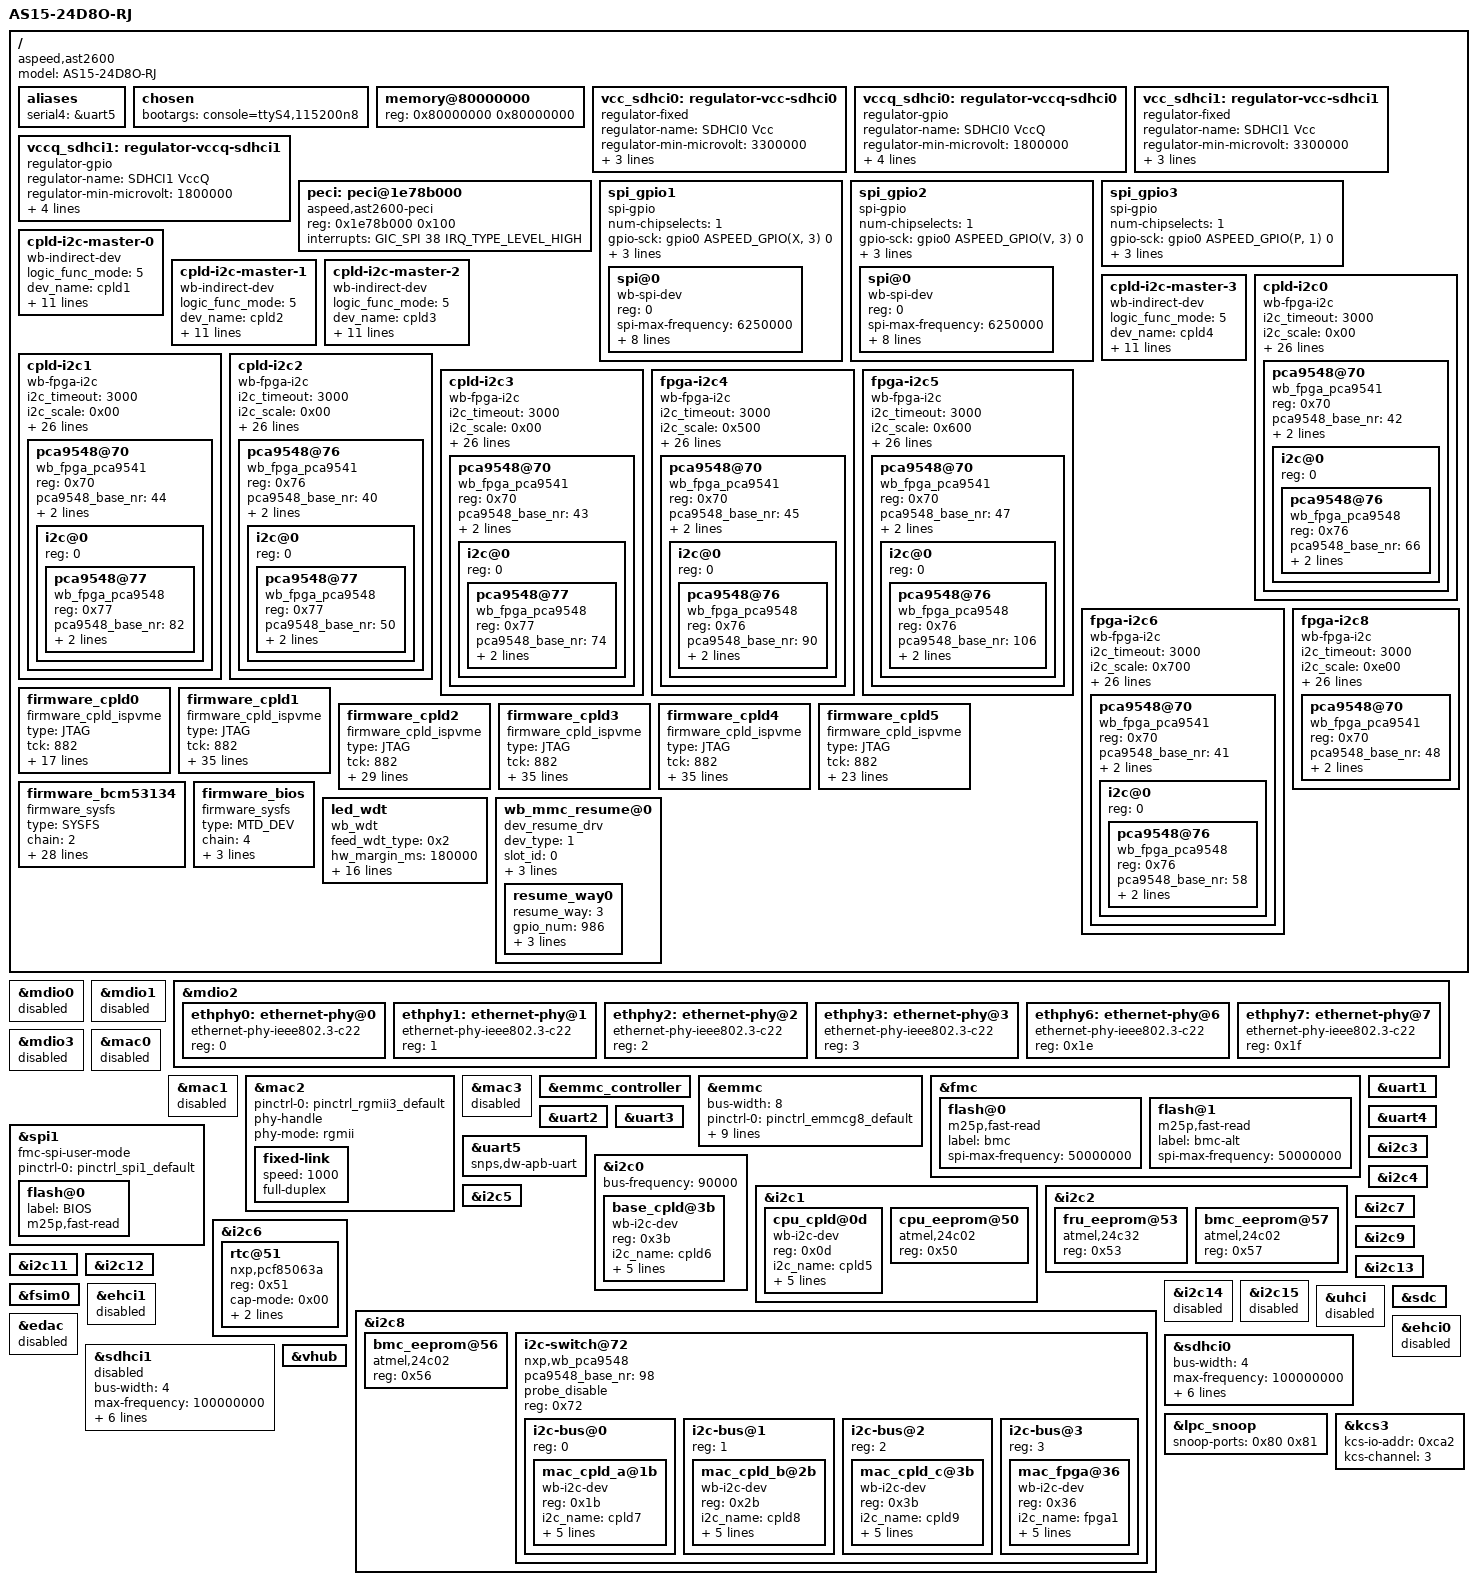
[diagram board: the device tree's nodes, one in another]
// SPDX-License-Identifier: GPL-2.0-or-later
// Copyright 2019 IBM Corp.

/dts-v1/;

#include "aspeed-g6.dtsi"
#include <dt-bindings/gpio/aspeed-gpio.h>

/ {
    model = "AS15-24D8O-RJ";
    compatible = "aspeed,ast2600";

    aliases {
        serial4 = &uart5;
    };

    chosen {
        bootargs = "console=ttyS4,115200n8";
    };

    memory@80000000 {
        device_type = "memory";
        reg = <0x80000000 0x80000000>;
    };

    vcc_sdhci0: regulator-vcc-sdhci0 {
        compatible = "regulator-fixed";
        regulator-name = "SDHCI0 Vcc";
        regulator-min-microvolt = <3300000>;
        regulator-max-microvolt = <3300000>;
        gpios = <&gpio0 ASPEED_GPIO(V, 0) GPIO_ACTIVE_HIGH>;
        enable-active-high;
    };

    vccq_sdhci0: regulator-vccq-sdhci0 {
        compatible = "regulator-gpio";
        regulator-name = "SDHCI0 VccQ";
        regulator-min-microvolt = <1800000>;
        regulator-max-microvolt = <3300000>;
        gpios = <&gpio0 ASPEED_GPIO(V, 1) GPIO_ACTIVE_HIGH>;
        gpios-states = <1>;
        states = <3300000 1>,<1800000 0>;
    };

    vcc_sdhci1: regulator-vcc-sdhci1 {
        compatible = "regulator-fixed";
        regulator-name = "SDHCI1 Vcc";
        regulator-min-microvolt = <3300000>;
        regulator-max-microvolt = <3300000>;
        gpios = <&gpio0 ASPEED_GPIO(V, 2) GPIO_ACTIVE_HIGH>;
        enable-active-high;
    };

    vccq_sdhci1: regulator-vccq-sdhci1 {
        compatible = "regulator-gpio";
        regulator-name = "SDHCI1 VccQ";
        regulator-min-microvolt = <1800000>;
        regulator-max-microvolt = <3300000>;
        gpios = <&gpio0 ASPEED_GPIO(V, 3) GPIO_ACTIVE_HIGH>;
        gpios-states = <1>;
        states = <3300000 1>,<1800000 0>;
    };

    peci: peci@1e78b000 {
        compatible = "aspeed,ast2600-peci";
        reg = <0x1e78b000 0x100>;
        interrupts = <GIC_SPI 38 IRQ_TYPE_LEVEL_HIGH>;
    };

    spi_gpio1 {
        compatible = "spi-gpio";
        status = "okay";
        #address-cells = <1>;
        #size-cells = <0>;
        num-chipselects = <1>;

        gpio-sck = <&gpio0 ASPEED_GPIO(X, 3) 0>;
        gpio-mosi = <&gpio0 ASPEED_GPIO(X, 4) 0>;
        gpio-miso = <&gpio0 ASPEED_GPIO(X, 5) 0>;
        cs-gpios = <&gpio0 ASPEED_GPIO(X, 0) 0>;
        spi@0 {
            compatible = "wb-spi-dev";
            reg = <0>;
            spi-max-frequency = <6250000>;
            spi-cpha;
            spi-cpol;
            spi_dev_name = "fpga0";
            data_bus_width    = <4>;
            addr_bus_width    = <4>;
            per_rd_len        = <4>;
            per_wr_len        = <4>;
            spi_len        = <0x2000>;
        };
    };

    spi_gpio2 {
        compatible = "spi-gpio";
        status = "okay";
        #address-cells = <1>;
        #size-cells = <0>;
        num-chipselects = <1>;

        gpio-sck = <&gpio0 ASPEED_GPIO(V, 3) 0>;
        gpio-mosi = <&gpio0 ASPEED_GPIO(Y, 2) 0>;
        gpio-miso = <&gpio0 ASPEED_GPIO(Y, 1) 0>;
        cs-gpios = <&gpio0 ASPEED_GPIO(Y, 3) 0>;

        spi@0 {
            compatible = "wb-spi-dev";
            reg = <0>;
            spi-max-frequency = <6250000>;
            spi-cpha;
            spi-cpol;
            spi_dev_name = "cpld0";
            data_bus_width    = <1>;
            addr_bus_width    = <2>;
            per_rd_len        = <1>;
            per_wr_len        = <1>;
            spi_len        = <0x140>;
        };
    };

    spi_gpio3 {
        compatible = "spi-gpio";
        status = "okay";
        #address-cells = <1>;
        #size-cells = <0>;
        num-chipselects = <1>;

        gpio-sck = <&gpio0 ASPEED_GPIO(P, 1) 0>;
        gpio-mosi = <&gpio0 ASPEED_GPIO(P, 3) 0>;
        gpio-miso = <&gpio0 ASPEED_GPIO(P, 2) 0>;
        cs-gpios = <&gpio0 ASPEED_GPIO(P, 4) 0>;
    };

    cpld-i2c-master-0 {
        compatible = "wb-indirect-dev";
        logic_func_mode = <5>;
        dev_name = "cpld1";
        logic_dev_name = "/dev/cpld0";
        data_bus_width    = <4>;
        addr_bus_width    = <1>;
        wr_data        = <0x100>;
        wr_data_width     = <4>;
        addr_low       = <0x104>;
        addr_high      = <0x105>;
        rd_data        = <0x106>;
        rd_data_width     = <4>;
        opt_ctl        = <0x10a>;
        indirect_len   = <0x200>;
    };

    cpld-i2c-master-1 {
        compatible = "wb-indirect-dev";
        logic_func_mode = <5>;
        dev_name = "cpld2";
        logic_dev_name = "/dev/cpld0";
        data_bus_width    = <4>;
        addr_bus_width    = <1>;
        wr_data        = <0x110>;
        wr_data_width     = <4>;
        addr_low       = <0x114>;
        addr_high      = <0x115>;
        rd_data        = <0x116>;
        rd_data_width     = <4>;
        opt_ctl        = <0x11a>;
        indirect_len   = <0x200>;
    };

    cpld-i2c-master-2 {
        compatible = "wb-indirect-dev";
        logic_func_mode = <5>;
        dev_name = "cpld3";
        logic_dev_name = "/dev/cpld0";
        data_bus_width    = <4>;
        addr_bus_width    = <1>;
        wr_data        = <0x120>;
        wr_data_width     = <4>;
        addr_low       = <0x124>;
        addr_high      = <0x125>;
        rd_data        = <0x126>;
        rd_data_width     = <4>;
        opt_ctl        = <0x12a>;
        indirect_len   = <0x200>;
    };

    cpld-i2c-master-3 {
        compatible = "wb-indirect-dev";
        logic_func_mode = <5>;
        dev_name = "cpld4";
        logic_dev_name = "/dev/cpld0";
        data_bus_width    = <4>;
        addr_bus_width    = <1>;
        wr_data        = <0x130>;
        wr_data_width     = <4>;
        addr_low       = <0x134>;
        addr_high      = <0x135>;
        rd_data        = <0x136>;
        rd_data_width     = <4>;
        opt_ctl        = <0x13a>;
        indirect_len   = <0x230>;
    };

   cpld-i2c0 {
       compatible = "wb-fpga-i2c";
       i2c_timeout             = <3000>;
       i2c_scale               = <0x00>;
       i2c_filter              = <0x04>;
       i2c_stretch             = <0x08>;
       i2c_ext_9548_exits_flag = <0x0c>;
       i2c_ext_9548_addr       = <0x10>;
       i2c_ext_9548_chan       = <0x14>;
       i2c_in_9548_chan        = <0x18>;
       i2c_slave               = <0x1c>;
       i2c_reg                 = <0x20>;
       i2c_reg_len             = <0x30>;
       i2c_data_len            = <0x34>;
       i2c_ctrl                = <0x38>;
       i2c_status              = <0x3c>;
       i2c_err_vec             = <0x48>;
       i2c_data_buf            = <0x100>;
       dev_name                = "/dev/cpld1";
       i2c_scale_value         = <0x4e>;
       i2c_filter_value        = <0x7c>;
       i2c_stretch_value       = <0x7c>;
       i2c_func_mode           = <6>;
       i2c_adap_reset_flag     = <0>;
       i2c_reset_addr          = <0x7c>;
       i2c_reset_on            = <0x00000001>;
       i2c_reset_off           = <0x00000000>;
       i2c_rst_delay_b         = <0>; /* delay time before reset(us) */
       i2c_rst_delay           = <1>; /* reset time(us) */
       i2c_rst_delay_a         = <1>; /* delay time after reset(us) */
       pca9548@70 {
           compatible = "wb_fpga_pca9541";
           reg = <0x70>;  
           #address-cells = <1>;
           #size-cells = <0>;
           pca9548_base_nr = <42>;
           fpga_9548_flag = <1>;        /* 1: internal 9548 2: external 9548 */
           fpga_9548_reset_flag = <0>;  /* 1: reset, 0: no bit */
           i2c@0 {
               reg = <0>;
               pca9548@76 {
                   compatible = "wb_fpga_pca9548";
                   reg = <0x76>;  
                   #address-cells = <1>;
                   #size-cells = <0>;
                   pca9548_base_nr = <66>;
                   fpga_9548_flag = <2>;
                   fpga_9548_reset_flag = <1>;
               };
           };
       };
   };

    cpld-i2c1 {
        compatible = "wb-fpga-i2c";
        i2c_timeout             = <3000>;
        i2c_scale               = <0x00>;
        i2c_filter              = <0x04>;
        i2c_stretch             = <0x08>;
        i2c_ext_9548_exits_flag = <0x0c>;
        i2c_ext_9548_addr       = <0x10>;
        i2c_ext_9548_chan       = <0x14>;
        i2c_in_9548_chan        = <0x18>;
        i2c_slave               = <0x1c>;
        i2c_reg                 = <0x20>;
        i2c_reg_len             = <0x30>;
        i2c_data_len            = <0x34>;
        i2c_ctrl                = <0x38>;
        i2c_status              = <0x3c>;
        i2c_err_vec             = <0x48>;
        i2c_data_buf            = <0x100>;
        dev_name                = "/dev/cpld2";
        i2c_scale_value         = <0x4e>;
        i2c_filter_value        = <0x7c>;
        i2c_stretch_value       = <0x7c>;
        i2c_func_mode           = <6>;
        i2c_adap_reset_flag     = <0>;
        i2c_reset_addr          = <0x7c>;
        i2c_reset_on            = <0x00000001>;
        i2c_reset_off           = <0x00000000>;
        i2c_rst_delay_b         = <0>; /* delay time before reset(us) */
        i2c_rst_delay           = <1>; /* reset time(us) */
        i2c_rst_delay_a         = <1>; /* delay time after reset(us) */
        pca9548@70 {
            compatible = "wb_fpga_pca9541";
            reg = <0x70>;  
            #address-cells = <1>;
            #size-cells = <0>;
            pca9548_base_nr = <44>;
            fpga_9548_flag = <1>;        /* 1: internal 9548 2: external 9548 */
            fpga_9548_reset_flag = <0>;  /* 1: reset, 0: no bit */
            i2c@0 {
                reg = <0>;
                pca9548@77 {
                    compatible = "wb_fpga_pca9548";
                    reg = <0x77>;  
                    #address-cells = <1>;
                    #size-cells = <0>;
                    pca9548_base_nr = <82>;
                    fpga_9548_flag = <2>;
                    fpga_9548_reset_flag = <1>;
                };
            };
        };
    };

    cpld-i2c2 {
        compatible = "wb-fpga-i2c";
        i2c_timeout             = <3000>;
        i2c_scale               = <0x00>;
        i2c_filter              = <0x04>;
        i2c_stretch             = <0x08>;
        i2c_ext_9548_exits_flag = <0x0c>;
        i2c_ext_9548_addr       = <0x10>;
        i2c_ext_9548_chan       = <0x14>;
        i2c_in_9548_chan        = <0x18>;
        i2c_slave               = <0x1c>;
        i2c_reg                 = <0x20>;
        i2c_reg_len             = <0x30>;
        i2c_data_len            = <0x34>;
        i2c_ctrl                = <0x38>;
        i2c_status              = <0x3c>;
        i2c_err_vec             = <0x48>;
        i2c_data_buf            = <0x100>;
        dev_name                = "/dev/cpld3";
        i2c_scale_value         = <0x4e>;
        i2c_filter_value        = <0x7c>;
        i2c_stretch_value       = <0x7c>;
        i2c_func_mode           = <6>;
        i2c_adap_reset_flag     = <0>;
        i2c_reset_addr          = <0x7c>;
        i2c_reset_on            = <0x00000001>;
        i2c_reset_off           = <0x00000000>;
        i2c_rst_delay_b         = <0>; /* delay time before reset(us) */
        i2c_rst_delay           = <1>; /* reset time(us) */
        i2c_rst_delay_a         = <1>; /* delay time after reset(us) */

        pca9548@76 {
            compatible = "wb_fpga_pca9541";
            reg = <0x76>;  
            #address-cells = <1>;
            #size-cells = <0>;
            pca9548_base_nr = <40>;
            fpga_9548_flag = <1>;        /* 1: internal 9548 2: external 9548 */
            fpga_9548_reset_flag = <0>;  /* 1: reset, 0: no bit */
            i2c@0 {
                reg = <0>;
                pca9548@77 {
                    compatible = "wb_fpga_pca9548";
                    reg = <0x77>;  
                    #address-cells = <1>;
                    #size-cells = <0>;
                    pca9548_base_nr = <50>;
                    fpga_9548_flag = <2>;
                    fpga_9548_reset_flag = <1>;
                };
            };
        };
    };

    cpld-i2c3 {
        compatible = "wb-fpga-i2c";
        i2c_timeout             = <3000>;
        i2c_scale               = <0x00>;
        i2c_filter              = <0x04>;
        i2c_stretch             = <0x08>;
        i2c_ext_9548_exits_flag = <0x0c>;
        i2c_ext_9548_addr       = <0x10>;
        i2c_ext_9548_chan       = <0x14>;
        i2c_in_9548_chan        = <0x18>;
        i2c_slave               = <0x1c>;
        i2c_reg                 = <0x20>;
        i2c_reg_len             = <0x30>;
        i2c_data_len            = <0x34>;
        i2c_ctrl                = <0x38>;
        i2c_status              = <0x3c>;
        i2c_err_vec             = <0x48>;
        i2c_data_buf            = <0x100>;
        dev_name                = "/dev/cpld4";
        i2c_scale_value         = <0x4e>;
        i2c_filter_value        = <0x7c>;
        i2c_stretch_value       = <0x7c>;
        i2c_func_mode           = <6>;
        i2c_adap_reset_flag     = <0>;
        i2c_reset_addr          = <0x7c>;
        i2c_reset_on            = <0x00000001>;
        i2c_reset_off           = <0x00000000>;
        i2c_rst_delay_b         = <0>; /* delay time before reset(us) */
        i2c_rst_delay           = <1>; /* reset time(us) */
        i2c_rst_delay_a         = <1>; /* delay time after reset(us) */

        pca9548@70 {
            compatible = "wb_fpga_pca9541";
            reg = <0x70>;  
            #address-cells = <1>;
            #size-cells = <0>;
            pca9548_base_nr = <43>;
            fpga_9548_flag = <1>;        /* 1: internal 9548 2: external 9548 */
            fpga_9548_reset_flag = <0>;  /* 1: reset, 0: no bit */
            i2c@0 {
                reg = <0>;
                pca9548@77 {
                    compatible = "wb_fpga_pca9548";
                    reg = <0x77>;  
                    #address-cells = <1>;
                    #size-cells = <0>;
                    pca9548_base_nr = <74>;
                    fpga_9548_flag = <2>;
                    fpga_9548_reset_flag = <1>;
                };
            };
        };
    };

    fpga-i2c4 {
        compatible = "wb-fpga-i2c";
        i2c_timeout             = <3000>;
        i2c_scale               = <0x500>;
        i2c_filter              = <0x504>;
        i2c_stretch             = <0x508>;
        i2c_ext_9548_exits_flag = <0x50c>;
        i2c_ext_9548_addr       = <0x510>;
        i2c_ext_9548_chan       = <0x514>;
        i2c_in_9548_chan        = <0x518>;
        i2c_slave               = <0x51c>;
        i2c_reg                 = <0x520>;
        i2c_reg_len             = <0x530>;
        i2c_data_len            = <0x534>;
        i2c_ctrl                = <0x538>;
        i2c_status              = <0x53c>;
        i2c_err_vec             = <0x548>;
        i2c_data_buf            = <0x580>;
        dev_name                = "/dev/fpga0";
        i2c_scale_value         = <0x4e>;
        i2c_filter_value        = <0x7c>;
        i2c_stretch_value       = <0x7c>;
        i2c_func_mode           = <5>;
        i2c_adap_reset_flag     = <0>;
        i2c_reset_addr          = <0x4c>;
        i2c_reset_on            = <0x00000001>;
        i2c_reset_off           = <0x00000000>;
        i2c_rst_delay_b         = <0>; /* delay time before reset(us) */
        i2c_rst_delay           = <1>; /* reset time(us) */
        i2c_rst_delay_a         = <1>; /* delay time after reset(us) */

        pca9548@70 {
            compatible = "wb_fpga_pca9541";
            reg = <0x70>;  
            #address-cells = <1>;
            #size-cells = <0>;
            pca9548_base_nr = <45>;
            fpga_9548_flag = <1>;        /* 1: internal 9548 2: external 9548 */
            fpga_9548_reset_flag = <0>;  /* 1: reset, 0: no bit */
            i2c@0 {
                reg = <0>;
                pca9548@76 {
                    compatible = "wb_fpga_pca9548";
                    reg = <0x76>;  
                    #address-cells = <1>;
                    #size-cells = <0>;
                    pca9548_base_nr = <90>;
                    fpga_9548_flag = <2>;
                    fpga_9548_reset_flag = <1>;
                };
            };
        };
    };

    fpga-i2c5 {
        compatible = "wb-fpga-i2c";
        i2c_timeout             = <3000>;
        i2c_scale               = <0x600>;
        i2c_filter              = <0x604>;
        i2c_stretch             = <0x608>;
        i2c_ext_9548_exits_flag = <0x60c>;
        i2c_ext_9548_addr       = <0x610>;
        i2c_ext_9548_chan       = <0x614>;
        i2c_in_9548_chan        = <0x618>;
        i2c_slave               = <0x61c>;
        i2c_reg                 = <0x620>;
        i2c_reg_len             = <0x630>;
        i2c_data_len            = <0x634>;
        i2c_ctrl                = <0x638>;
        i2c_status              = <0x63c>;
        i2c_err_vec             = <0x648>;
        i2c_data_buf            = <0x680>;
        dev_name                = "/dev/fpga0";
        i2c_scale_value         = <0x4e>;
        i2c_filter_value        = <0x7c>;
        i2c_stretch_value       = <0x7c>;
        i2c_func_mode           = <5>;
        i2c_adap_reset_flag     = <0>;
        i2c_reset_addr          = <0x50>;
        i2c_reset_on            = <0x00000001>;
        i2c_reset_off           = <0x00000000>;
        i2c_rst_delay_b         = <0>; /* delay time before reset(us) */
        i2c_rst_delay           = <1>; /* reset time(us) */
        i2c_rst_delay_a         = <1>; /* delay time after reset(us) */
        pca9548@70 {
            compatible = "wb_fpga_pca9541";
            reg = <0x70>;  
            #address-cells = <1>;
            #size-cells = <0>;
            pca9548_base_nr = <47>;
            fpga_9548_flag = <1>;        /* 1: internal 9548 2: external 9548 */
            fpga_9548_reset_flag = <0>;  /* 1: reset, 0: no bit */
            i2c@0 {
                reg = <0>;
                pca9548@76 {
                    compatible = "wb_fpga_pca9548";
                    reg = <0x76>;  
                    #address-cells = <1>;
                    #size-cells = <0>;
                    pca9548_base_nr = <106>;
                    fpga_9548_flag = <2>;
                    fpga_9548_reset_flag = <1>;
                };
            };
        };
    };

    fpga-i2c6 {
        compatible = "wb-fpga-i2c";
        i2c_timeout             = <3000>;
        i2c_scale               = <0x700>;
        i2c_filter              = <0x704>;
        i2c_stretch             = <0x708>;
        i2c_ext_9548_exits_flag = <0x70c>;
        i2c_ext_9548_addr       = <0x710>;
        i2c_ext_9548_chan       = <0x714>;
        i2c_in_9548_chan        = <0x718>;
        i2c_slave               = <0x71c>;
        i2c_reg                 = <0x720>;
        i2c_reg_len             = <0x730>;
        i2c_data_len            = <0x734>;
        i2c_ctrl                = <0x738>;
        i2c_status              = <0x73c>;
        i2c_err_vec             = <0x748>;
        i2c_data_buf            = <0x780>;
        dev_name                = "/dev/fpga0";
        i2c_scale_value         = <0x4e>;
        i2c_filter_value        = <0x7c>;
        i2c_stretch_value       = <0x7c>;
        i2c_func_mode           = <5>;
        i2c_adap_reset_flag     = <0>;
        i2c_reset_addr          = <0x54>;
        i2c_reset_on            = <0x00000001>;
        i2c_reset_off           = <0x00000000>;
        i2c_rst_delay_b         = <0>; /* delay time before reset(us) */
        i2c_rst_delay           = <1>; /* reset time(us) */
        i2c_rst_delay_a         = <1>; /* delay time after reset(us) */
        pca9548@70 {
            compatible = "wb_fpga_pca9541";
            reg = <0x70>;  
            #address-cells = <1>;
            #size-cells = <0>;
            pca9548_base_nr = <41>;
            fpga_9548_flag = <1>;        /* 1: internal 9548 2: external 9548 */
            fpga_9548_reset_flag = <0>;  /* 1: reset, 0: no bit */
            i2c@0 {
                reg = <0>;
                pca9548@76 {
                    compatible = "wb_fpga_pca9548";
                    reg = <0x76>;  
                    #address-cells = <1>;
                    #size-cells = <0>;
                    pca9548_base_nr = <58>;
                    fpga_9548_flag = <2>;
                    fpga_9548_reset_flag = <1>;
                };
            };
        };
    };

    fpga-i2c8 {
        compatible = "wb-fpga-i2c";
        i2c_timeout             = <3000>;
        i2c_scale               = <0xe00>;
        i2c_filter              = <0xe04>;
        i2c_stretch             = <0xe08>;
        i2c_ext_9548_exits_flag = <0xe0c>;
        i2c_ext_9548_addr       = <0xe10>;
        i2c_ext_9548_chan       = <0xe14>;
        i2c_in_9548_chan        = <0xe18>;
        i2c_slave               = <0xe1c>;
        i2c_reg                 = <0xe20>;
        i2c_reg_len             = <0xe30>;
        i2c_data_len            = <0xe34>;
        i2c_ctrl                = <0xe38>;
        i2c_status              = <0xe3c>;
        i2c_err_vec             = <0xe48>;
        i2c_data_buf            = <0xe80>;
        dev_name                = "/dev/fpga0";
        i2c_scale_value         = <0x4e>;
        i2c_filter_value        = <0x7c>;
        i2c_stretch_value       = <0x7c>;
        i2c_func_mode           = <5>;
        i2c_adap_reset_flag     = <0>;
        i2c_reset_addr          = <0x5c>;
        i2c_reset_on            = <0x00000001>;
        i2c_reset_off           = <0x00000000>;
        i2c_rst_delay_b         = <0>; /* delay time before reset(us) */
        i2c_rst_delay           = <1>; /* reset time(us) */
        i2c_rst_delay_a         = <1>; /* delay time after reset(us) */

        pca9548@70 {
            compatible = "wb_fpga_pca9541";
            reg = <0x70>;  
            #address-cells = <1>;
            #size-cells = <0>;
            pca9548_base_nr = <48>;
            fpga_9548_flag = <1>;        /* 1: internal 9548 2: external 9548 */
            fpga_9548_reset_flag = <0>;  /* 1: reset, 0: no bit */
        };
    };

    /*BASE CPLD*/
    firmware_cpld0 {
        compatible  = "firmware_cpld_ispvme";
        type        = "JTAG";
        tck      = <882>;
        tdi      = <881>;
        tms      = <883>;
        tdo      = <884>;
        en_gpio_0  = <885>;
        en_level_0 = <1>;
        en_gpio_1  = <880>;
        en_level_1 = <1>;
        en_gpio_2  = <886>;
        en_level_2 = <0>;
        chain        = <1>;
        chip_index  = <1>;
        en_logic_dev_0 = "/dev/cpld6";
        en_logic_addr_0 = <0x45>;
        en_logic_mask_0 = <0xfc>;
        en_logic_en_val_0 = <0x2>;
        en_logic_dis_val_0 = <0x0>;
        en_logic_width_0 = <1>;
    };

    /* MAC CPLD_A CPLD_B*/
    firmware_cpld1 {
        compatible  = "firmware_cpld_ispvme";
        type        = "JTAG";
        tck      = <882>;
        tdi      = <881>;
        tms      = <883>;
        tdo      = <884>;
        en_gpio_0  = <880>;
        en_level_0 = <1>;
        en_gpio_1  = <885>;
        en_level_1 = <0>;
        en_gpio_2  = <886>;
        en_level_2 = <1>;
        chain        = <2>;
        chip_index  = <1>;
        en_logic_dev_0 = "/dev/cpld6";
        en_logic_addr_0 = <0x45>;
        en_logic_mask_0 = <0xfc>;
        en_logic_en_val_0 = <0x02>;
        en_logic_dis_val_0 = <0x0>;
        en_logic_width_0 = <1>;
        en_logic_dev_1 = "/dev/cpld6";
        en_logic_addr_1 = <0x46>;
        en_logic_mask_1 = <0xf8>;
        en_logic_en_val_1 = <0x2>;
        en_logic_dis_val_1 = <0x0>;
        en_logic_width_1 = <1>;
        en_logic_dev_2 = "/dev/cpld6";
        en_logic_addr_2 = <0x49>;
        en_logic_mask_2 = <0xfc>;
        en_logic_en_val_2 = <0x2>;
        en_logic_dis_val_2 = <0x3>;
        en_logic_width_2 = <1>;
        en_logic_dev_3 = "/dev/cpld6";
        en_logic_addr_3 = <0x4b>;
        en_logic_mask_3 = <0x00>;
        en_logic_en_val_3 = <0xfe>;
        en_logic_dis_val_3 = <0x1f>;
        en_logic_width_3 = <1>;
    };

    /*MAC CPLD_C*/
    firmware_cpld2 {
        compatible  = "firmware_cpld_ispvme";
        type        = "JTAG";
        tck      = <882>;
        tdi      = <881>;
        tms      = <883>;
        tdo      = <884>;
        en_gpio_0  = <880>;
        en_level_0 = <1>;
        en_gpio_1  = <885>;
        en_level_1 = <0>;
        en_gpio_2  = <886>;
        en_level_2 = <1>;
        chain        = <3>;
        chip_index  = <1>;
        en_logic_dev_0 = "/dev/cpld6";
        en_logic_addr_0 = <0x45>;
        en_logic_mask_0 = <0xfc>;
        en_logic_en_val_0 = <0x02>;
        en_logic_dis_val_0 = <0x0>;
        en_logic_width_0 = <1>;
        en_logic_dev_1 = "/dev/cpld6";
        en_logic_addr_1 = <0x46>;
        en_logic_mask_1 = <0xf8>;
        en_logic_en_val_1 = <0x2>;
        en_logic_dis_val_1 = <0x0>;
        en_logic_width_1 = <1>;
        en_logic_dev_2 = "/dev/cpld6";
        en_logic_addr_2 = <0x49>;
        en_logic_mask_2 = <0xfc>;
        en_logic_en_val_2 = <0x1>;
        en_logic_dis_val_2 = <0x3>;
        en_logic_width_2 = <1>;
    };

    /* FAN CPLD*/
    firmware_cpld3 {
        compatible  = "firmware_cpld_ispvme";
        type        = "JTAG";
        tck      = <882>;
        tdi      = <881>;
        tms      = <883>;
        tdo      = <884>;
        en_gpio_0  = <880>;
        en_level_0 = <1>;
        en_gpio_1  = <885>;
        en_level_1 = <0>;
        en_gpio_2  = <886>;
        en_level_2 = <1>;
        chain        = <4>;
        chip_index  = <1>;
        en_logic_dev_0 = "/dev/cpld6";
        en_logic_addr_0 = <0x45>;
        en_logic_mask_0 = <0xfc>;
        en_logic_en_val_0 = <0x02>;
        en_logic_dis_val_0 = <0x0>;
        en_logic_width_0 = <1>;
        en_logic_dev_1 = "/dev/cpld6";
        en_logic_addr_1 = <0x46>;
        en_logic_mask_1 = <0xf8>;
        en_logic_en_val_1 = <0x4>;
        en_logic_dis_val_1 = <0x0>;
        en_logic_width_1 = <1>;
        en_logic_dev_2 = "/dev/cpld6";
        en_logic_addr_2 = <0x49>;
        en_logic_mask_2 = <0xfc>;
        en_logic_en_val_2 = <0x2>;
        en_logic_dis_val_2 = <0x0>;
        en_logic_width_2 = <1>;
        en_logic_dev_3 = "/dev/cpld6";
        en_logic_addr_3 = <0x4b>;
        en_logic_mask_3 = <0x00>;
        en_logic_en_val_3 = <0xfd>;
        en_logic_dis_val_3 = <0xff>;
        en_logic_width_3 = <1>;
    };

    /*MGMT CPLD*/
    firmware_cpld4 {
        compatible  = "firmware_cpld_ispvme";
        type        = "JTAG";
        tck      = <882>;
        tdi      = <881>;
        tms      = <883>;
        tdo      = <884>;
        en_gpio_0  = <880>;
        en_level_0 = <1>;
        en_gpio_1  = <885>;
        en_level_1 = <0>;
        en_gpio_2  = <886>;
        en_level_2 = <1>;
        chain        = <5>;
        chip_index  = <1>;
        en_logic_dev_0 = "/dev/cpld6";
        en_logic_addr_0 = <0x45>;
        en_logic_mask_0 = <0xfc>;
        en_logic_en_val_0 = <0x2>;
        en_logic_dis_val_0 = <0x0>;
        en_logic_width_0 = <1>;
        en_logic_dev_1 = "/dev/cpld6";
        en_logic_addr_1 = <0x46>;
        en_logic_mask_1 = <0x00>;
        en_logic_en_val_1 = <0x3>;
        en_logic_dis_val_1 = <0x0>;
        en_logic_width_1 = <1>;
        en_logic_dev_2 = "/dev/cpld6";
        en_logic_addr_2 = <0x4b>;
        en_logic_mask_2 = <0x00>;
        en_logic_en_val_2 = <0xfb>;
        en_logic_dis_val_2 = <0xff>;
        en_logic_width_2 = <1>;
        en_logic_dev_3 = "/dev/cpld6";
        en_logic_addr_3 = <0x49>;
        en_logic_mask_3 = <0xfc>;
        en_logic_en_val_3 = <0x2>;
        en_logic_dis_val_3 = <0x0>;
        en_logic_width_3 = <1>;
    };

     /* CPU CPLD*/
    firmware_cpld5 {
        compatible  = "firmware_cpld_ispvme";
        type        = "JTAG";
        tck      = <882>;
        tdi      = <881>;
        tms      = <883>;
        tdo      = <884>;
        en_gpio_0  = <880>;
        en_level_0 = <1>;
        en_gpio_1  = <885>;
        en_level_1 = <0>;
        en_gpio_2  = <886>;
        en_level_2 = <1>;
        chain        = <6>;
        chip_index  = <1>;
        en_logic_dev_0 = "/dev/cpld6";
        en_logic_addr_0 = <0x45>;
        en_logic_mask_0 = <0xfc>;
        en_logic_en_val_0 = <0x02>;
        en_logic_dis_val_0 = <0x0>;
        en_logic_width_0 = <1>;
        en_logic_dev_1 = "/dev/cpld6";
        en_logic_addr_1 = <0x46>;
        en_logic_mask_1 = <0xf8>;
        en_logic_en_val_1 = <0x1>;
        en_logic_dis_val_1 = <0x0>;
        en_logic_width_1 = <1>;
    };


    /* 53134 upgrade */
    firmware_bcm53134 {
        compatible  = "firmware_sysfs";
        type        = "SYSFS";
        chain        = <2>;
        chip_index  = <1>;
        sysfs_name    = "/sys/bus/spi/devices/spi2.0/eeprom";
        en_gpio_0  = <941>;
        en_level_0 = <0>;
        en_logic_dev_0 = "/dev/cpld6";
        en_logic_addr_0 = <0x3d>;
        en_logic_mask_0 = <0xfe>;
        en_logic_en_val_0 = <0x00>;
        en_logic_dis_val_0 = <0x1>;
        en_logic_width_0 = <1>;
        en_logic_dev_1 = "/dev/cpld6";
        en_logic_addr_1 = <0x42>;
        en_logic_mask_1 = <0xfe>;
        en_logic_en_val_1 = <0x0>;
        en_logic_dis_val_1 = <0x1>;
        en_logic_width_1 = <1>;
        en_logic_dev_2 = "/dev/cpld6";
        en_logic_addr_2 = <0x45>;
        en_logic_mask_2 = <0xfc>;
        en_logic_en_val_2 = <0x2>;
        en_logic_dis_val_2 = <0x0>;
        en_logic_width_2 = <1>;
        en_logic_dev_3 = "/dev/cpld6";
        en_logic_addr_3 = <0x46>;
        en_logic_mask_3 = <0xf8>;
        en_logic_en_val_3 = <0x6>;
        en_logic_dis_val_3 = <0x0>;
        en_logic_width_3 = <1>;
    };

    /* BIOS Upgrade link */
    firmware_bios {
        compatible  = "firmware_sysfs";
        type        = "MTD_DEV";
        chain       = <4>;
        chip_index  = <1>;
        mtd_name    = "BIOS";
        flash_base  = <0x0>;
    };

    led_wdt: led_wdt {
        compatible = "wb_wdt";
        feed_wdt_type = /bits/ 8 <0x2>;   /* 0: does not feed the dog, 1:hrtimer feeds the dog, 2: threads feed the dog */
        hw_margin_ms = <180000>;          /* Timeout period */
        feed_time = <30000>;              /* Dog feeding time */
        config_dev_name = "/dev/cpld6";   /* Configuring CPLD */
        config_mode = /bits/ 8 <2>;       /* 1:GPIO feed the dog, 2: logic device feed the dog */
        priv_func_mode = /bits/ 8 <1>;    /* 1:i2c, 2:pcie, 3:IO, 4:Device file */
        enable_reg = <0xb6>;              /* Enable register. Note: This led_wdt has no enable register and is compatible with driver configuration as a dog feed register */
        enable_val = /bits/ 8 <0x1>;      /* Enable value */
        disable_val = /bits/ 8 <0x0>;     /* Disabled value */
        enable_mask = /bits/ 8 <0x1>;     /* Enable the mask */
        timeout_cfg_reg = <0xb8>;         /* Time setting register */
        timeleft_cfg_reg = <0xb9>;         /* Residual time register */
        hw_algo = "toggle";               /* toggle: Flip, level: level level */
        feed_dev_name = "/dev/cpld6";     /* Logic device feed dog register */
        feed_reg = <0xb7>;                /* Dog feed register */
        active_val = /bits/ 8 <0x1>;      /* Dog feed value */
        logic_func_mode = /bits/ 8 <0x1>; /* 1:i2c, 2:pcie, 3:IO, 4:Device file */
        timer_accuracy = <6000>;          /* 6s */
    };

    wb_mmc_resume@0 {
        compatible = "dev_resume_drv";
        dev_type   = <1>;                             /* 1: MMC; 2: SSD */
        slot_id    = <0>;                             /* emmc controller0 */
        bit_mask   = <0x01>;
        reg_intf_name   = "mmc_resume_register";
        unreg_intf_name = "mmc_resume_unregister";

        resume_way0 {
            resume_way    = <3>;                     /* way3 DEV_RESUME_WAY2_CTL_GPIO */
            gpio_num      = <986>;
            active_level  = <0>;
            reset_delay   = <10000>;
            dereset_delay = <5000>;
        };
    };


};

&mdio0 {
    status = "disabled";
};

&mdio1 {
    status = "disabled";
};

&mdio2 {
    status = "okay";

    ethphy0: ethernet-phy@0 {
        compatible = "ethernet-phy-ieee802.3-c22";
        reg = <0>;
    };
    ethphy1: ethernet-phy@1 {
        compatible = "ethernet-phy-ieee802.3-c22";
        reg = <1>;
    };
    ethphy2: ethernet-phy@2 {
        compatible = "ethernet-phy-ieee802.3-c22";
        reg = <2>;
    };
    ethphy3: ethernet-phy@3 {
        compatible = "ethernet-phy-ieee802.3-c22";
        reg = <3>;
    };
    ethphy6: ethernet-phy@6 {
        compatible = "ethernet-phy-ieee802.3-c22";
        reg = <0x1e>;
    };
    ethphy7: ethernet-phy@7 {
        compatible = "ethernet-phy-ieee802.3-c22";
        reg = <0x1f>;
    };
};

&mdio3 {
    status = "disabled";
};

&mac0 {
    status = "disabled";
};

&mac1 {
    status = "disabled";
};

&mac2 {
    status = "okay";
    pinctrl-names = "default";
    pinctrl-0 = <&pinctrl_rgmii3_default>;
    phy-handle;
    phy-mode = "rgmii";
    fixed-link {
        speed = <1000>;
        full-duplex;
    };
};

&mac3 {
    status = "disabled";
};

&emmc_controller {
    status = "okay";
};

&emmc {
	bus-width = <8>;
	pinctrl-0 = <&pinctrl_emmcg8_default>;
 	non-removable;
	no-sd;
	no-sdio;
 	max-frequency = <50000000>;
	clk-phase-mmc-hs200 = <0 27>, <1 185>;
	cap-mmc-hw-reset;
    reset_gpio = <794>; /* reset emmc gpio GPIOB6*/
	reset_on = <0>;
	reset_off = <1>;
    status = "okay";
 };

&fmc {
    status = "okay";
    flash@0 {
    status = "okay";
        m25p,fast-read;
        label = "bmc";
        spi-max-frequency = <50000000>;
#include "facebook-bmc-g6-flash-layout-64.dtsi"
    };
    flash@1 {
        status = "okay";
        m25p,fast-read;
        label = "bmc-alt";
        spi-max-frequency = <50000000>;
#include "facebook-bmc-g6-alt-flash-layout-64.dtsi"
    };
};

&spi1 {
    status = "okay";
    fmc-spi-user-mode;
    pinctrl-names = "default";
    pinctrl-0 = <&pinctrl_spi1_default>;

    flash@0 {
        status = "okay";
        label = "BIOS";
        m25p,fast-read;
    };
};

&uart1 {
    status = "okay";
};

&uart2 {
    status = "okay";
};

&uart3 {
    status = "okay";
};

&uart4 {
    status = "okay";
};

&uart5 {
	// Workaround for A0
	compatible = "snps,dw-apb-uart";
};

&i2c0 {
    status = "okay";
    bus-frequency = <90000>;
    base_cpld@3b {
        compatible = "wb-i2c-dev";
        reg = <0x3b>;
        i2c_name = "cpld6";
        data_bus_width = <1>;
        addr_bus_width = <1>;
        per_rd_len = <256>;
        per_wr_len = <256>;
        i2c_len    = <0x100>;
    };
};

&i2c1 {
    status = "okay";
    cpu_cpld@0d {
        compatible = "wb-i2c-dev";
        reg = <0x0d>;
        i2c_name = "cpld5";
        data_bus_width = <1>;
        addr_bus_width = <1>;
        per_rd_len = <256>;
        per_wr_len = <256>;
        i2c_len    = <0x100>;
    };

    cpu_eeprom@50 {
        compatible = "atmel,24c02";
        reg = <0x50>;
    };
};

&i2c2 {
    status = "okay";
    fru_eeprom@53 {
        compatible = "atmel,24c32";
        reg = <0x53>;
        status = "okay";
    };
    bmc_eeprom@57 {
        compatible = "atmel,24c02";
        reg = <0x57>;
        status = "okay";
    };
};

&i2c3 {
    status = "okay";
};

&i2c4 {
    status = "okay";
};

&i2c5 {
    status = "okay";
};

&i2c6 {
    status = "okay";
    rtc@51 {
        compatible = "nxp,pcf85063a";
        reg = <0x51>;
        status = "okay";
        cap-mode = /bits/ 8 <0x00>;
        clock-freq = /bits/ 8 <0x07>;
        accuracy-value = /bits/ 8 <0x09>;
    };
};

&i2c7 {
    status = "okay";
};

&i2c8 {
    status = "okay";
    bmc_eeprom@56 {
        compatible = "atmel,24c02";
        reg = <0x56>;
        status = "okay";
    };
    i2c-switch@72 {
        compatible = "nxp,wb_pca9548";
        #address-cells = <1>;
        #size-cells = <0>;
        pca9548_base_nr = <98>; 
        probe_disable;
        reg = <0x72>;

        i2c-bus@0 {
            #address-cells = <1>;
            #size-cells = <0>;
            reg = <0>;

            // MAC board CPLDA
            mac_cpld_a@1b {
                compatible = "wb-i2c-dev";
                reg = <0x1b>;
                i2c_name = "cpld7";
                data_bus_width = <1>;
                addr_bus_width = <1>;
                per_rd_len = <256>;
                per_wr_len = <256>;
                i2c_len    = <0x100>;
            };
        };
        i2c-bus@1 {
            #address-cells = <1>;
            #size-cells = <0>;
            reg = <1>;

            // MAC board CPLDB
            mac_cpld_b@2b {
                compatible = "wb-i2c-dev";
                reg = <0x2b>;
                i2c_name = "cpld8";
                data_bus_width = <1>;
                addr_bus_width = <1>;
                per_rd_len = <256>;
                per_wr_len = <256>;
                i2c_len    = <0x100>;
            };
        };
        i2c-bus@2 {
            #address-cells = <1>;
            #size-cells = <0>;
            reg = <2>;

            mac_cpld_c@3b {
                compatible = "wb-i2c-dev";
                reg = <0x3b>;
                i2c_name = "cpld9";
                data_bus_width = <1>;
                addr_bus_width = <1>;
                per_rd_len = <256>;
                per_wr_len = <256>;
                i2c_len    = <0x100>;
            };
        };
        i2c-bus@3 {
            #address-cells = <1>;
            #size-cells = <0>;
            reg = <3>;

        mac_fpga@36 {
                compatible = "wb-i2c-dev";
                reg = <0x36>;
                i2c_name = "fpga1";
                data_bus_width = <4>;
                addr_bus_width = <4>;
                per_rd_len = <4>;
                per_wr_len = <4>;
                i2c_len    = <0x1000>;
            };
        };
    };
};

&i2c9 {
    status = "okay";
};

&i2c11 {
    status = "okay";
};

&i2c12 {
    status = "okay";
};

&i2c13 {
    status = "okay";
};

&i2c14 {
    status = "disabled";
};

&i2c15 {
    status = "disabled";
};

&fsim0 {
    status = "okay";
};

&ehci1 {
    status = "disabled";
};

&uhci {
    status = "disabled";
};

&sdc {
    status = "okay";
};

&edac {
    status = "disabled";
};

/*
 * The signal voltage of sdhci0 and sdhci1 on AST2600-A2 EVB is able to be
 * toggled by GPIO pins.
 * In the reference design, GPIOV0 of AST2600-A2 EVB is connected to the
 * power load switch that provides 3.3v to sdhci0 vdd, GPIOV1 is connected to
 * a 1.8v and a 3.3v power load switch that provides signal voltage to
 * sdhci0 bus.
 * If GPIOV0 is active high, sdhci0 is enabled, otherwise, sdhci0 is disabled.
 * If GPIOV1 is active high, 3.3v power load switch is enabled, sdhci0 signal
 * voltage is 3.3v, otherwise, 1.8v power load switch will be enabled,
 * sdhci0 signal voltage becomes 1.8v.
 * AST2600-A2 EVB also supports toggling signal voltage for sdhci1.
 * The design is the same as sdhci0, it uses GPIOV2 as power-gpio and GPIOV3
 * as power-switch-gpio.
 */
&sdhci0 {
    status = "okay";
    bus-width = <4>;
    max-frequency = <100000000>;
    sdhci-drive-type = /bits/ 8 <3>;
    sdhci-caps-mask = <0x7 0x0>;
    sdhci,wp-inverted;
    vmmc-supply = <&vcc_sdhci0>;
    vqmmc-supply = <&vccq_sdhci0>;
    clk-phase-sd-hs = <7>, <200>;
};

&sdhci1 {
    status = "disabled";
    bus-width = <4>;
    max-frequency = <100000000>;
    sdhci-drive-type = /bits/ 8 <3>;
    sdhci-caps-mask = <0x7 0x0>;
    sdhci,wp-inverted;
    vmmc-supply = <&vcc_sdhci1>;
    vqmmc-supply = <&vccq_sdhci1>;
    clk-phase-sd-hs = <7>, <200>;
};

&ehci0 {
    status = "disabled";
};

&ehci1 {
    status = "disabled";
};

&vhub {
    status = "okay";
};

&lpc_snoop {
    status = "okay";
    snoop-ports = <0x80 0x81>;
};

&kcs3 {
    status = "okay";
    kcs-io-addr = <0xca2>;
    kcs-channel = <3>;
};
